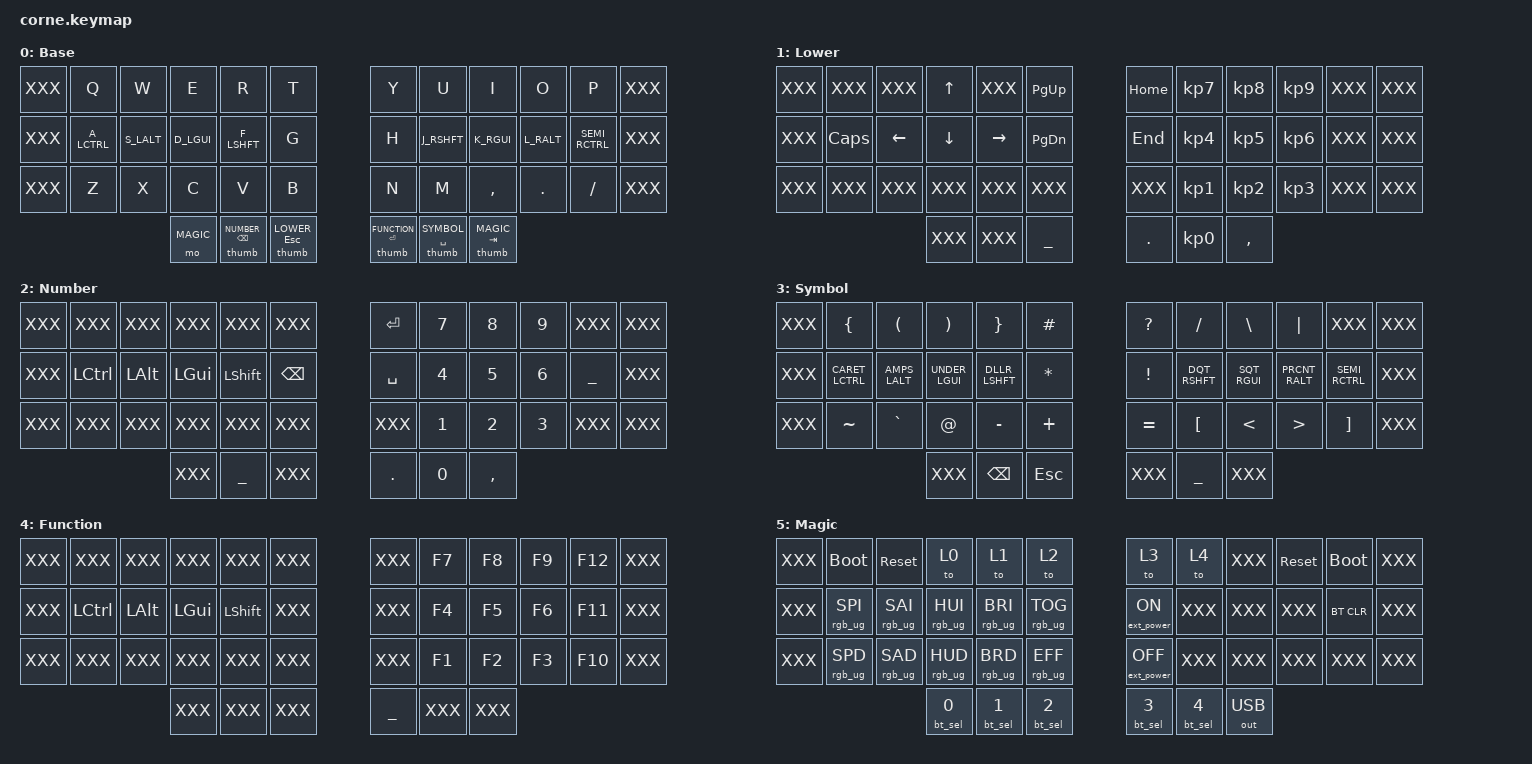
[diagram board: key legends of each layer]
#include <behaviors.dtsi>

#include <dt-bindings/zmk/keys.h>
#include <dt-bindings/zmk/ext_power.h>
#include <dt-bindings/zmk/bt.h>
#include <dt-bindings/zmk/rgb.h>
#include <dt-bindings/zmk/outputs.h>

#include "zmk-helpers/helper.h"
#include "zmk-helpers/key-labels/42.h"

#include "./mouse.dtsi"

#define LEFT_HAND_KEYS   LT5 LT4 LT3 LT2 LT1 LT0 \
                         LM5 LM4 LM3 LM2 LM1 LM0 \
                         LB5 LB4 LB3 LB2 LB1 LB0

#define RIGHT_HAND_KEYS  RT0 RT1 RT2 RT3 RT4 RT5 \
                         RM0 RM1 RM2 RM3 RM4 RM5 \
                         RB0 RB1 RB2 RB3 RB4 RB5

#define THUMB_KEYS       LH2 LH1 LH0     RH0 RH1 RH2

#include "general.h"
#include "homerow_mods.h"
#include "custom_behaviors.h"

#define BASE      0
#define LOWER     1
#define NUMBER    2
#define SYMBOL    3
#define FUNCTION  4
#define MAGIC     5

ZMK_LAYER(Base,
// ╭───────────────┬───────────────┬───────────────┬───────────────┬───────────────┬───────────────╮   ╭───────────────┬───────────────┬───────────────┬───────────────┬───────────────┬───────────────╮
     XXX             &kp Q           &kp W           &kp E           &kp R           &kp T               &kp Y           &kp U           &kp I           &kp O           &kp P           XXX
// ├───────────────┼───────────────┼───────────────┼───────────────┼───────────────┼───────────────┤   ├───────────────┼───────────────┼───────────────┼───────────────┼───────────────┼───────────────┤
     XXX             A_LCTRL         S_LALT          D_LGUI          F_LSHFT         &kp G               &kp H           J_RSHFT         K_RGUI          L_RALT          SEMI_RCTRL      XXX
// ├───────────────┼───────────────┼───────────────┼───────────────┼───────────────┼───────────────┤   ├───────────────┼───────────────┼───────────────┼───────────────┼───────────────┼───────────────┤
     XXX             &kp Z           &kp X           &kp C           &kp V           &kp B               &kp N           &kp M           &kp COMMA       &kp DOT         &kp FSLH        XXX
// ╰───────────────┴───────────────┴───────────────┴───────────────┴───────────────┴───────────────╯   ╰───────────────┴───────────────┴───────────────┴───────────────┴───────────────┴───────────────╯
//                                     ╭───────────────────┬────────────────────┬───────────────╮         ╭───────────────────┬─────────────────────┬─────────────────────╮
                                         &mo MAGIC           &thumb NUMBER BSPC   &thumb LOWER ESC          &thumb FUNCTION RET &thumb SYMBOL SPACE   &thumb MAGIC TAB
//                                     ╰───────────────────┴────────────────────┴───────────────╯         ╰───────────────────┴─────────────────────┴─────────────────────╯
)

ZMK_LAYER(Lower,
// ╭───────────────┬───────────────┬───────────────┬───────────────┬───────────────┬───────────────╮   ╭───────────────┬───────────────┬───────────────┬───────────────┬───────────────────────┬───────────────╮
     XXX             XXX             XXX             &kp UP          XXX             &kp PG_UP           &kp HOME        &kp KP_N7       &kp KP_N8       &kp KP_N9       XXX                     XXX
// ├───────────────┼───────────────┼───────────────┼───────────────┼───────────────┼───────────────┤   ├───────────────┼───────────────┼───────────────┼───────────────┼───────────────────────┼───────────────┤
     XXX             &kp CAPS        &kp LEFT        &kp DOWN        &kp RIGHT       &kp PG_DN           &kp END         &kp KP_N4       &kp KP_N5       &kp KP_N6       XXX                     XXX
// ├───────────────┼───────────────┼───────────────┼───────────────┼───────────────┼───────────────┤   ├───────────────┼───────────────┼───────────────┼───────────────┼───────────────────────┼───────────────┤
     XXX             XXX             XXX             XXX             XXX             XXX                 XXX             &kp KP_N1       &kp KP_N2       &kp KP_N3       XXX                     XXX
// ╰───────────────┴───────────────┴───────────────┴───────────────┴───────────────┴───────────────╯   ╰───────────────┴───────────────┴───────────────┴───────────────┴───────────────────────┴───────────────╯
//                                              ╭───────────────┬───────────────┬───────────────╮         ╭───────────────┬───────────────┬───────────────╮
                                                  XXX             XXX             ___                       &kp DOT         &kp KP_N0       &kp COMMA
//                                              ╰───────────────┴───────────────┴───────────────╯         ╰───────────────┴───────────────┴───────────────╯
)

ZMK_LAYER(Number,
// ╭───────────────┬───────────────┬───────────────┬───────────────┬───────────────┬───────────────╮   ╭───────────────┬───────────────┬───────────────┬───────────────┬───────────────┬─────────────────╮
     XXX             XXX             XXX             XXX             XXX             XXX                 &kp RET         &kp N7          &kp N8          &kp N9          XXX             XXX
// ├───────────────┼───────────────┼───────────────┼───────────────┼───────────────┼───────────────┤   ├───────────────┼───────────────┼───────────────┼───────────────┼───────────────┼─────────────────┤
     XXX             &kp LCTRL       &kp LALT        &kp LGUI        &kp LSHFT       &kp BSPC            &kp SPC         &kp N4          &kp N5          &kp N6          &kp UNDER       XXX
// ├───────────────┼───────────────┼───────────────┼───────────────┼───────────────┼───────────────┤   ├───────────────┼───────────────┼───────────────┼───────────────┼───────────────┼─────────────────┤
     XXX             XXX             XXX             XXX             XXX             XXX                 XXX             &kp N1          &kp N2          &kp N3          XXX             XXX
// ╰───────────────┴───────────────┴───────────────┴───────────────┴───────────────┴───────────────╯   ╰───────────────┴───────────────┴───────────────┴───────────────┴───────────────┴─────────────────╯
//                                              ╭───────────────┬───────────────┬───────────────╮         ╭───────────────┬───────────────┬───────────────╮
                                                  XXX             ___             XXX                       &kp DOT         &kp N0          &kp COMMA
//                                              ╰───────────────┴───────────────┴───────────────╯         ╰───────────────┴───────────────┴───────────────╯
)

ZMK_LAYER(Symbol,
// ╭───────────────┬───────────────┬───────────────┬───────────────┬───────────────┬───────────────╮   ╭───────────────┬───────────────┬───────────────┬───────────────┬───────────────┬───────────────╮
     XXX             &kp LBRC        &kp LPAR        &kp RPAR        &kp RBRC        &kp HASH            &kp QMARK       &kp FSLH        &kp BSLH        &kp PIPE        XXX             XXX
// ├───────────────┼───────────────┼───────────────┼───────────────┼───────────────┼───────────────┤   ├───────────────┼───────────────┼───────────────┼───────────────┼───────────────┼───────────────┤
     XXX             CARET_LCTRL     AMPS_LALT       UNDER_LGUI      DLLR_LSHFT      &kp STAR            &kp EXCL        DQT_RSHFT       SQT_RGUI        PRCNT_RALT      SEMI_RCTRL      XXX
// ├───────────────┼───────────────┼───────────────┼───────────────┼───────────────┼───────────────┤   ├───────────────┼───────────────┼───────────────┼───────────────┼───────────────┼───────────────┤
     XXX             &kp TILDE       &kp GRAVE       &kp AT          &kp MINUS       &kp PLUS            &kp EQUAL       &kp LBKT        &kp LT          &kp GT          &kp RBKT        XXX
// ╰───────────────┴───────────────┴───────────────┴───────────────┴───────────────┴───────────────╯   ╰───────────────┴───────────────┴───────────────┴───────────────┴───────────────┴───────────────╯
//                                              ╭───────────────┬───────────────┬───────────────╮         ╭───────────────┬───────────────┬───────────────╮
                                                  XXX             &kp BSPC        &kp ESC                   XXX             ___             XXX
//                                              ╰───────────────┴───────────────┴───────────────╯         ╰───────────────┴───────────────┴───────────────╯
)

ZMK_LAYER(Function,
// ╭───────────────┬───────────────┬───────────────┬───────────────┬───────────────┬───────────────╮   ╭───────────────┬───────────────┬───────────────┬───────────────┬───────────────┬─────────────────╮
     XXX             XXX             XXX             XXX             XXX             XXX                 XXX             &kp F7          &kp F8          &kp F9          &kp F12         XXX
// ├───────────────┼───────────────┼───────────────┼───────────────┼───────────────┼───────────────┤   ├───────────────┼───────────────┼───────────────┼───────────────┼───────────────┼─────────────────┤
     XXX             &kp LCTRL       &kp LALT        &kp LGUI        &kp LSHFT       XXX                 XXX             &kp F4          &kp F5          &kp F6          &kp F11         XXX
// ├───────────────┼───────────────┼───────────────┼───────────────┼───────────────┼───────────────┤   ├───────────────┼───────────────┼───────────────┼───────────────┼───────────────┼─────────────────┤
     XXX             XXX             XXX             XXX             XXX             XXX                 XXX             &kp F1          &kp F2          &kp F3          &kp F10         XXX
// ╰───────────────┴───────────────┴───────────────┴───────────────┴───────────────┴───────────────╯   ╰───────────────┴───────────────┴───────────────┴───────────────┴───────────────┴─────────────────╯
//                                              ╭───────────────┬───────────────┬───────────────╮         ╭───────────────┬───────────────┬───────────────╮
                                                  XXX             XXX             XXX                       ___             XXX             XXX
//                                              ╰───────────────┴───────────────┴───────────────╯         ╰───────────────┴───────────────┴───────────────╯
)

ZMK_LAYER(Magic,
// ╭───────────────┬─────────────────┬─────────────────┬─────────────────┬─────────────────┬─────────────────╮   ╭───────────────────┬─────────────────┬───────────────┬───────────────┬───────────────┬─────────────────╮
     XXX             &bootloader       &sys_reset        &to 0             &to 1             &to 2                 &to 3               &to 4             XXX             &sys_reset      &bootloader     XXX
// ├───────────────┼─────────────────┼─────────────────┼─────────────────┼─────────────────┼─────────────────┤   ├───────────────────┼─────────────────┼───────────────┼───────────────┼───────────────┼─────────────────┤
     XXX             &rgb_ug RGB_SPI   &rgb_ug RGB_SAI   &rgb_ug RGB_HUI   &rgb_ug RGB_BRI   &rgb_ug RGB_TOG       &ext_power EP_ON    XXX               XXX             XXX             &bt BT_CLR      XXX
// ├───────────────┼─────────────────┼─────────────────┼─────────────────┼─────────────────┼─────────────────┤   ├───────────────────┼─────────────────┼───────────────┼───────────────┼───────────────┼─────────────────┤
     XXX             &rgb_ug RGB_SPD   &rgb_ug RGB_SAD   &rgb_ug RGB_HUD   &rgb_ug RGB_BRD   &rgb_ug RGB_EFF       &ext_power EP_OFF   XXX               XXX             XXX             XXX             XXX
// ╰───────────────┴─────────────────┴─────────────────┴─────────────────┴─────────────────┴─────────────────╯   ╰───────────────────┴─────────────────┴───────────────┴───────────────┴───────────────┴─────────────────╯
//                                                        ╭───────────────┬───────────────┬───────────────╮         ╭───────────────┬───────────────┬───────────────╮
                                                            &bt_sel 0       &bt_sel 1       &bt_sel 2                 &bt_sel 3       &bt_sel 4       &out OUT_USB
//                                                        ╰───────────────┴───────────────┴───────────────╯         ╰───────────────┴───────────────┴───────────────╯
)
//
////ZMK_LAYER(Template,
////// ╭───────────────┬───────────────┬───────────────┬───────────────┬───────────────┬───────────────╮   ╭───────────────┬───────────────┬───────────────┬───────────────┬───────────────┬───────────────╮
////     XXX             XXX             XXX             XXX             XXX             XXX                 XXX             XXX             XXX             XXX             XXX             XXX
////// ├───────────────┼───────────────┼───────────────┼───────────────┼───────────────┼───────────────┤   ├───────────────┼───────────────┼───────────────┼───────────────┼───────────────┼───────────────┤
////     XXX             XXX             XXX             XXX             XXX             XXX                 XXX             XXX             XXX             XXX             XXX             XXX
////// ├───────────────┼───────────────┼───────────────┼───────────────┼───────────────┼───────────────┤   ├───────────────┼───────────────┼───────────────┼───────────────┼───────────────┼───────────────┤
////     XXX             XXX             XXX             XXX             XXX             XXX                 XXX             XXX             XXX             XXX             XXX             XXX
////// ╰───────────────┴───────────────┴───────────────┴───────────────┴───────────────┴───────────────╯   ╰───────────────┴───────────────┴───────────────┴───────────────┴───────────────┴───────────────╯
//////                                              ╭───────────────┬───────────────┬───────────────╮         ╭───────────────┬───────────────┬───────────────╮
////                                                  XXX             XXX              XXX                      XXX         XXX             XXX
//////                                              ╰───────────────┴───────────────┴───────────────╯         ╰───────────────┴───────────────┴───────────────╯
////)<F9>ooo
